VERSION ""

NS_ :

BS_:

BU_: XXX

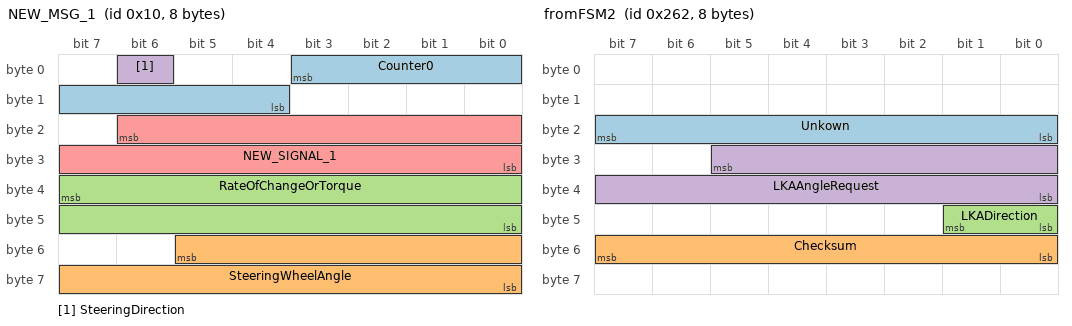
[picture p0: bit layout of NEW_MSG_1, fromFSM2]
BO_ 16 NEW_MSG_1: 8 XXX
 SG_ Counter0 : 3|8@0+ (1,0) [0|511] "" XXX
 SG_ SteeringWheelAngle : 53|14@0+ (1,0) [0|65535] "" XXX
 SG_ RateOfChangeOrTorque : 39|16@0+ (1,-32768) [0|65535] "" XXX
 SG_ SteeringDirection : 6|1@0+ (1,0) [0|1] "" XXX
 SG_ NEW_SIGNAL_1 : 22|15@0+ (1,0) [0|65535] "" XXX

BO_ 32 NEW_MSG_2: 8 XXX
 SG_ AcceleratorPedal : 17|10@0+ (0.1,0) [0|1023] "" XXX

BO_ 648 NEW_MSG_3: 8 XXX
 SG_ Counter : 0|3@1+ (1,0) [0|7] "" XXX
 SG_ Brake : 24|8@1+ (1,4) [0|255] "" XXX

BO_ 465 NEW_MSG_4: 8 XXX
 SG_ ZeroWhileBraking : 3|1@0+ (1,0) [0|1] "" XXX

BO_ 298 NEW_MSG_5: 8 XXX
 SG_ ZeroWhileBraking : 38|1@0+ (1,0) [0|1] "" XXX

BO_ 609 SteeringServo: 8 XXX
 SG_ SteeringAngle : 21|14@0+ (1,0) [0|65535] "" XXX

BO_ 582 NEW_MSG_6: 8 XXX
 SG_ SteeringWheelAngle : 23|16@0+ (1,0) [0|65535] "" XXX
 SG_ SteeringWheelRateOfChange : 0|9@0+ (1,0) [0|255] "" XXX

BO_ 81 fromFSM0: 8 XXX

BO_ 608 fromFSM1: 8 XXX
 SG_ TimeGapMaybe : 0|8@1+ (1,0) [0|255] "" XXX

BO_ 610 fromFSM2: 8 XXX
 SG_ Unkown : 23|8@0+ (1,0) [0|255] "" XXX
 SG_ Checksum : 55|8@0+ (1,0) [0|255] "" XXX
 SG_ LKADirection : 41|2@0+ (1,0) [0|3] "" XXX
 SG_ LKAAngleRequest : 29|14@0+ (0.04,-327.68) [0|16383] "" XXX

BO_ 624 fromFSM3: 8 XXX

BO_ 794 fromFSM4: 8 XXX

BO_ 821 untitled: 8 XXX

BO_ 1021 fromFSM5: 8 XXX

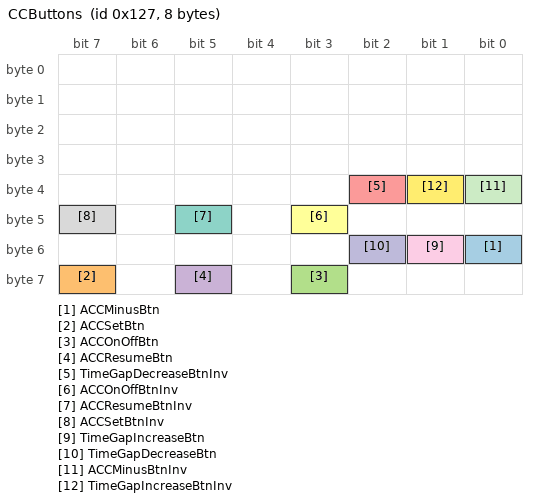
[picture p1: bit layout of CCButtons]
BO_ 295 CCButtons: 8 XXX
 SG_ ACCMinusBtn : 48|1@0+ (1,0) [0|1] "" XXX
 SG_ ACCSetBtn : 63|1@0+ (1,0) [0|1] "" XXX
 SG_ ACCOnOffBtn : 59|1@0+ (1,0) [0|1] "" XXX
 SG_ ACCResumeBtn : 61|1@0+ (1,0) [0|1] "" XXX
 SG_ TimeGapDecreaseBtnInv : 34|1@0+ (1,0) [0|2047] "" XXX
 SG_ ACCOnOffBtnInv : 43|1@0+ (1,0) [0|1] "" XXX
 SG_ ACCResumeBtnInv : 45|1@0+ (1,0) [0|1] "" XXX
 SG_ ACCSetBtnInv : 47|1@0+ (1,0) [0|1] "" XXX
 SG_ TimeGapIncreaseBtn : 49|1@0+ (1,0) [0|1] "" XXX
 SG_ TimeGapDecreaseBtn : 50|1@0+ (1,0) [0|1] "" XXX
 SG_ ACCMinusBtnInv : 32|1@0+ (1,0) [0|1] "" XXX
 SG_ TimeGapIncreaseBtnInv : 33|1@0+ (1,0) [0|1] "" XXX

CM_ SG_ 16 RateOfChangeOrTorque "Rate of change? Torque?";
CM_ SG_ 16 SteeringDirection "0 = CCW, 1=CW (turning left or right of center)";
CM_ SG_ 32 AcceleratorPedal "Unsure about scaling.";
CM_ SG_ 648 Brake "Something with brake pedal, presure, position.";
CM_ SG_ 465 ZeroWhileBraking "Turns zero while braking";
CM_ SG_ 298 ZeroWhileBraking "Turns zero while braking";
CM_ SG_ 582 SteeringWheelRateOfChange "Some rate of change for steering wheel?";
CM_ SG_ 608 TimeGapMaybe "When ACC turned on goes from 255 -> 2 Then from 2->1 when pressing longer time gap.";
CM_ SG_ 610 LKADirection "0=None, 1=Right, 2=Left";
CM_ SG_ 295 ACCMinusBtn "ACC Minus (-) button pressed";
CM_ SG_ 295 ACCSetBtn "Acc Set button (+) pressed";
CM_ SG_ 295 ACCOnOffBtn "Cruise control on/off button pressed";
CM_ SG_ 295 ACCResumeBtn "ACC Resume button pressed";
CM_ SG_ 295 TimeGapDecreaseBtnInv "Active zero when button pressed.";
CM_ SG_ 295 ACCOnOffBtnInv "Active zero when button pressed.";
CM_ SG_ 295 ACCResumeBtnInv "Active zero when button pressed.";
CM_ SG_ 295 ACCSetBtnInv "Active zero when button pressed.";
CM_ SG_ 295 TimeGapIncreaseBtn "Increase the time gap on ACC";
CM_ SG_ 295 TimeGapDecreaseBtn "Decrease the time gap on ACC";
CM_ SG_ 295 ACCMinusBtnInv "Active zero when button pressed.";
CM_ SG_ 295 TimeGapIncreaseBtnInv "Active zero when button pressed.";
